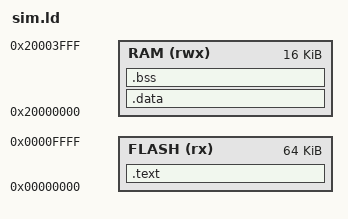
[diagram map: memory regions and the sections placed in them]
ENTRY(main)
MEMORY {
  FLASH (rx) : ORIGIN = 0x00000000, LENGTH = 64K
  RAM (rwx) : ORIGIN = 0x20000000, LENGTH = 16K
}
SECTIONS {
  .text : { *(.text*) *(.rodata*) } > FLASH
  .data : { *(.data*) } > RAM
  .bss : { *(.bss*) } > RAM
}
